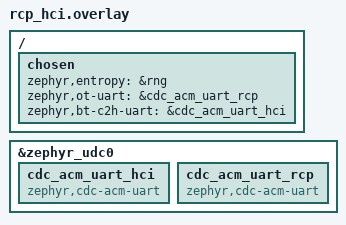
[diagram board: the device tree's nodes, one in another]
/*
 * Copyright (c) 2023 Nordic Semiconductor ASA
 *
 * SPDX-License-Identifier: LicenseRef-Nordic-5-Clause
 */

 / {
	chosen {
		zephyr,entropy = &rng;
		zephyr,ot-uart = &cdc_acm_uart_rcp;
		zephyr,bt-c2h-uart = &cdc_acm_uart_hci;
	};
};

&zephyr_udc0 {
	cdc_acm_uart_hci: cdc_acm_uart_hci {
		compatible = "zephyr,cdc-acm-uart";
	};
	cdc_acm_uart_rcp: cdc_acm_uart_rcp {
		compatible = "zephyr,cdc-acm-uart";
	};
};
